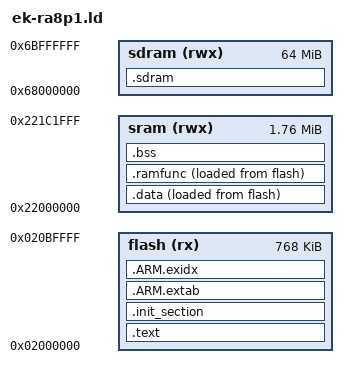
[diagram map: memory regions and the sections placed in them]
/****************************************************************************
 * boards/arm/ra8p/ek-ra8p1/scripts/ek-ra8p1.ld
 *
 * Licensed to the Apache Software Foundation (ASF) under one or more
 * contributor license agreements.  See the NOTICE file distributed with
 * this work for additional information regarding copyright ownership.  The
 * ASF licenses this file to you under the Apache License, Version 2.0 (the
 * "License"); you may not use this file except in compliance with the
 * License.  You may obtain a copy of the License at
 *
 *   http://www.apache.org/licenses/LICENSE-2.0
 *
 * Unless required by applicable law or agreed to in writing, software
 * distributed under the License is distributed on an "AS IS" BASIS, WITHOUT
 * WARRANTIES OR CONDITIONS OF ANY KIND, either express or implied.  See the
 * License for the specific language governing permissions and limitations
 * under the License.
 *
 ****************************************************************************/

/* The RA8P1 has:
 * - Code MRAM: 768KB CM85 core (0x02000000) + 256KB CM33 core (0x02C00000) 
 * - SRAM: 1404KB + 468KB (total ~1.8MB) starting at 0x22000000
 * - SDRAM: 64MB (external) starting at 0x68000000
 */

MEMORY
{
  flash (rx)   : ORIGIN = 0x02000000, LENGTH = 768K  /* Code MRAM for CM85 */
  sram (rwx)   : ORIGIN = 0x22000000, LENGTH = 1800K /* SRAM */
  sdram (rwx)  : ORIGIN = 0x68000000, LENGTH = 64M   /* External SDRAM */
}

OUTPUT_ARCH(arm)
EXTERN(_vectors)
ENTRY(_stext)
SECTIONS
{
    .text :
    {
        _stext = ABSOLUTE(.);
        *(.vectors)
        . = _stext + 0x400;
        KEEP(*(.rom_registers*))
        *(.text .text.*)
        *(.fixup)
        *(.gnu.warning)
        *(.rodata .rodata.*)
        *(.gnu.linkonce.t.*)
        *(.glue_7)
        *(.glue_7t)
        *(.got)
        *(.gcc_except_table)
        *(.gnu.linkonce.r.*)
        _etext = ABSOLUTE(.);
    } > flash

    .init_section :
    {
        _sinit = ABSOLUTE(.);
        KEEP(*(SORT_BY_INIT_PRIORITY(.init_array.*) SORT_BY_INIT_PRIORITY(.ctors.*)))
        KEEP(*(.init_array .ctors))
        _einit = ABSOLUTE(.);
    } > flash

    .ARM.extab :
    {
        *(.ARM.extab*)
    } >flash

    .ARM.exidx :
    {
        __exidx_start = ABSOLUTE(.);
        *(.ARM.exidx*)
        __exidx_end = ABSOLUTE(.);
    } >flash

    .data :
    {
        _sdata = ABSOLUTE(.);
        *(.data .data.*)
        *(.gnu.linkonce.d.*)
        CONSTRUCTORS
        . = ALIGN(4);
        _edata = ABSOLUTE(.);
    } > sram AT > flash

    _eronly = LOADADDR(.data);

    .ramfunc ALIGN(4):
    {
        _sramfuncs = ABSOLUTE(.);
        *(.ramfunc  .ramfunc.*)
        _eramfuncs = ABSOLUTE(.);
    } > sram AT > flash

    _framfuncs = LOADADDR(.ramfunc);

    .bss :
    {
        _sbss = ABSOLUTE(.);
        *(.bss .bss.*)
        *(.gnu.linkonce.b.*)
        *(COMMON)
        . = ALIGN(8);
        _ebss = ABSOLUTE(.);
    } > sram

    .sdram :
    {
        _sdram_start = ABSOLUTE(.);
        *(.sdram .sdram.*)
        _sdram_end = ABSOLUTE(.);
    } > sdram

    /* Stabs debugging sections. */

    .stab 0 : { *(.stab) }
    .stabstr 0 : { *(.stabstr) }
    .stab.excl 0 : { *(.stab.excl) }
    .stab.exclstr 0 : { *(.stab.exclstr) }
    .stab.index 0 : { *(.stab.index) }
    .stab.indexstr 0 : { *(.stab.indexstr) }
    .comment 0 : { *(.comment) }
    .debug_abbrev 0 : { *(.debug_abbrev) }
    .debug_info 0 : { *(.debug_info) }
    .debug_line 0 : { *(.debug_line) }
    .debug_pubnames 0 : { *(.debug_pubnames) }
    .debug_aranges 0 : { *(.debug_aranges) }
}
